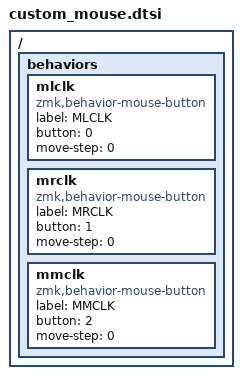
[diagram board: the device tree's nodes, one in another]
/ {
    behaviors {
        // 纯净左键点击 - 无移动
        mlclk: mlclk {
            compatible = "zmk,behavior-mouse-button";
            label = "MLCLK";
            #binding-cells = <0>;
            button = <0>;
            move-step = <0>; // 关键：移动步长为0
        };
        // 纯净右键点击 - 无移动
        mrclk: mrclk {
            compatible = "zmk,behavior-mouse-button";
            label = "MRCLK";
            #binding-cells = <0>;
            button = <1>;
            move-step = <0>; // 关键：移动步长为0
        };
        // 纯净中键点击 - 无移动
        mmclk: mmclk {
            compatible = "zmk,behavior-mouse-button";
            label = "MMCLK";
            #binding-cells = <0>;
            button = <2>;
            move-step = <0>; // 关键：移动步长为0
        };
    };
};
